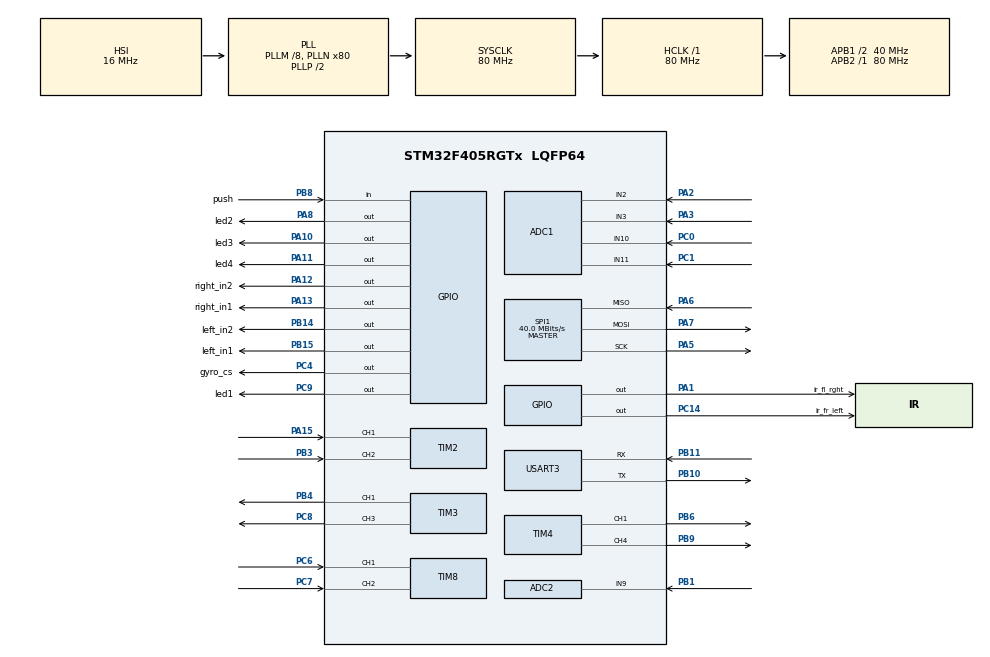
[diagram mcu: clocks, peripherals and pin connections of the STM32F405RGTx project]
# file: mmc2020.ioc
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ADC1.Channel-89\#ChannelRegularConversion=ADC_CHANNEL_10
ADC1.ClockPrescaler=ADC_CLOCK_SYNC_PCLK_DIV4
ADC1.NbrOfConversionFlag=1
ADC1.Rank-89\#ChannelRegularConversion=1
ADC1.SamplingTime-89\#ChannelRegularConversion=ADC_SAMPLETIME_3CYCLES
ADC1.master=1
ADC2.Channel-0\#ChannelRegularConversion=ADC_CHANNEL_9
ADC2.ClockPrescaler=ADC_CLOCK_SYNC_PCLK_DIV4
ADC2.NbrOfConversionFlag=1
ADC2.Rank-0\#ChannelRegularConversion=1
ADC2.SamplingTime-0\#ChannelRegularConversion=ADC_SAMPLETIME_3CYCLES
Mcu.Family=STM32F4
Mcu.Name=STM32F405RGTx
Mcu.Package=LQFP64
NVIC.PriorityGroup=NVIC_PRIORITYGROUP_4
PA1.GPIO_Label=ir_fl_rght
PA1.Signal=GPIO_Output
PA10.GPIO_Label=led3
PA10.Signal=GPIO_Output
PA11.GPIO_Label=led4
PA11.Signal=GPIO_Output
PA12.GPIO_Label=right_in2
PA12.Signal=GPIO_Output
PA13.GPIO_Label=right_in1
PA13.Signal=GPIO_Output
PA15.Signal=S_TIM2_CH1_ETR
PA2.Signal=ADCx_IN2
PA3.Signal=ADCx_IN3
PA5.Mode=Full_Duplex_Master
PA5.Signal=SPI1_SCK
PA6.Mode=Full_Duplex_Master
PA6.Signal=SPI1_MISO
PA7.Mode=Full_Duplex_Master
PA7.Signal=SPI1_MOSI
PA8.GPIO_Label=led2
PA8.Signal=GPIO_Output
PB1.Signal=ADCx_IN9
PB10.Mode=Asynchronous
PB10.Signal=USART3_TX
PB11.Mode=Asynchronous
PB11.Signal=USART3_RX
PB14.GPIO_Label=left_in2
PB14.Signal=GPIO_Output
PB15.GPIO_Label=left_in1
PB15.Signal=GPIO_Output
PB3.Signal=S_TIM2_CH2
PB4.Signal=S_TIM3_CH1
PB6.Signal=S_TIM4_CH1
PB8.GPIO_Label=push
PB8.Signal=GPIO_Input
PB9.Signal=S_TIM4_CH4
PC0.Signal=ADCx_IN10
PC1.Signal=ADCx_IN11
PC14-OSC32_IN.GPIO_Label=ir_fr_left
PC14-OSC32_IN.Signal=GPIO_Output
PC4.GPIO_Label=gyro_cs
PC4.Signal=GPIO_Output
PC6.Signal=S_TIM8_CH1
PC7.Signal=S_TIM8_CH2
PC8.Signal=S_TIM3_CH3
PC9.GPIO_Label=led1
PC9.Signal=GPIO_Output
PH0-OSC_IN.Mode=HSE-External-Oscillator
PH0-OSC_IN.Signal=RCC_OSC_IN
PH1-OSC_OUT.Mode=HSE-External-Oscillator
PH1-OSC_OUT.Signal=RCC_OSC_OUT
ProjectManager.HeapSize=0x200
ProjectManager.StackSize=0x400
ProjectManager.TargetToolchain=Makefile
RCC.48MHZClocksFreq_Value=40000000
RCC.AHBFreq_Value=80000000
RCC.APB1CLKDivider=RCC_HCLK_DIV2
RCC.APB1Freq_Value=40000000
RCC.APB1TimFreq_Value=80000000
RCC.APB2Freq_Value=80000000
RCC.APB2TimFreq_Value=80000000
RCC.CortexFreq_Value=80000000
RCC.HCLKFreq_Value=80000000
RCC.HSE_VALUE=20000000
RCC.HSI_VALUE=16000000
RCC.LSE_VALUE=32768
RCC.PLLM=8
RCC.PLLN=80
RCC.SYSCLKFreq_VALUE=80000000
RCC.SYSCLKSource=RCC_SYSCLKSOURCE_PLLCLK
RCC.VCOOutputFreq_Value=160000000
SH.ADCx_IN10.0=ADC1_IN10,IN10
SH.ADCx_IN11.0=ADC1_IN11,IN11
SH.ADCx_IN2.0=ADC1_IN2,IN2
SH.ADCx_IN3.0=ADC1_IN3,IN3
SH.ADCx_IN9.0=ADC2_IN9,IN9
SH.S_TIM2_CH1_ETR.0=TIM2_CH1,Encoder_Interface
SH.S_TIM2_CH2.0=TIM2_CH2,Encoder_Interface
SH.S_TIM3_CH1.0=TIM3_CH1,PWM Generation1 CH1
SH.S_TIM3_CH3.0=TIM3_CH3,PWM Generation3 CH3
SH.S_TIM4_CH1.0=TIM4_CH1,PWM Generation1 CH1
SH.S_TIM4_CH4.0=TIM4_CH4,PWM Generation4 CH4
SH.S_TIM8_CH1.0=TIM8_CH1,Encoder_Interface
SH.S_TIM8_CH2.0=TIM8_CH2,Encoder_Interface
SPI1.BaudRatePrescaler=SPI_BAUDRATEPRESCALER_2
SPI1.CalculateBaudRate=40.0 MBits/s
SPI1.Direction=SPI_DIRECTION_2LINES
SPI1.Mode=SPI_MODE_MASTER
SPI1.VirtualType=VM_MASTER
TIM3.Channel-PWM\ Generation1\ CH1=TIM_CHANNEL_1
TIM3.Channel-PWM\ Generation3\ CH3=TIM_CHANNEL_3
TIM4.Channel-PWM\ Generation1\ CH1=TIM_CHANNEL_1
TIM4.Channel-PWM\ Generation4\ CH4=TIM_CHANNEL_4
USART3.VirtualMode=VM_ASYNC
board=mmc2020

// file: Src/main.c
/**
  ******************************************************************************
  * @file           : main.c
  * @brief          : Main program body
  ******************************************************************************
  ** This notice applies to any and all portions of this file
  * that are not between comment pairs USER CODE BEGIN and
  * USER CODE END. Other portions of this file, whether
  * inserted by the user or by software development tools
  * are owned by their respective copyright owners.
  *
  * COPYRIGHT(c) 2020 STMicroelectronics
  *
  * Redistribution and use in source and binary forms, with or without modification,
  * are permitted provided that the following conditions are met:
  *   1. Redistributions of source code must retain the above copyright notice,
  *      this list of conditions and the following disclaimer.
  *   2. Redistributions in binary form must reproduce the above copyright notice,
  *      this list of conditions and the following disclaimer in the documentation
  *      and/or other materials provided with the distribution.
  *   3. Neither the name of STMicroelectronics nor the names of its contributors
  *      may be used to endorse or promote products derived from this software
  *      without specific prior written permission.
  *
  * THIS SOFTWARE IS PROVIDED BY THE COPYRIGHT HOLDERS AND CONTRIBUTORS "AS IS"
  * AND ANY EXPRESS OR IMPLIED WARRANTIES, INCLUDING, BUT NOT LIMITED TO, THE
  * IMPLIED WARRANTIES OF MERCHANTABILITY AND FITNESS FOR A PARTICULAR PURPOSE ARE
  * DISCLAIMED. IN NO EVENT SHALL THE COPYRIGHT HOLDER OR CONTRIBUTORS BE LIABLE
  * FOR ANY DIRECT, INDIRECT, INCIDENTAL, SPECIAL, EXEMPLARY, OR CONSEQUENTIAL
  * DAMAGES (INCLUDING, BUT NOT LIMITED TO, PROCUREMENT OF SUBSTITUTE GOODS OR
  * SERVICES; LOSS OF USE, DATA, OR PROFITS; OR BUSINESS INTERRUPTION) HOWEVER
  * CAUSED AND ON ANY THEORY OF LIABILITY, WHETHER IN CONTRACT, STRICT LIABILITY,
  * OR TORT (INCLUDING NEGLIGENCE OR OTHERWISE) ARISING IN ANY WAY OUT OF THE USE
  * OF THIS SOFTWARE, EVEN IF ADVISED OF THE POSSIBILITY OF SUCH DAMAGE.
  *
  ******************************************************************************
  */
#include "main.h"
#include "stm32f4xx_hal.h"
#include "adc.h"
#include "spi.h"
#include "tim.h"
#include "usart.h"
#include "gpio.h"

/* USER CODE BEGIN Includes */
#include "stdint.h"
/* USER CODE END Includes */

/* USER CODE BEGIN PV */
#define TRUE 1
#define FALSE 0
/* Private variables ---------------------------------------------------------*/

/* USER CODE END PV */

void SystemClock_Config(void);

/* USER CODE BEGIN PFP */
/* Private function prototypes -----------------------------------------------*/

/* USER CODE END PFP */

int main(void)
{

  /* MCU Configuration----------------------------------------------------------*/

  /* Reset of all peripherals, Initializes the Flash interface and the Systick. */
  HAL_Init();

  /* Configure the system clock */
  SystemClock_Config();

  /* Initialize all configured peripherals */
  MX_GPIO_Init();
  MX_ADC1_Init();
  MX_SPI1_Init();
  MX_TIM8_Init();
  MX_TIM2_Init();
  MX_TIM3_Init();
  MX_TIM4_Init();
  MX_USART3_UART_Init();
  MX_ADC2_Init();
  /* USER CODE BEGIN 2 */
  buzzerPwmOut(99,C_SCALE);
  HAL_Delay(1000);
  buzzerPwmOut(0,NORMAL);
  /* USER CODE END 2 */

  /* Infinite loop */
  /* USER CODE BEGIN WHILE */
  while (1)
  {
    if(Push()==TRUE){
      for(uint8_t i=0;i<16;i++){
        Led(i);
        HAL_Delay(500);
      }
    }
  /* USER CODE END WHILE */

  }

}

void SystemClock_Config(void)
{

  RCC_OscInitTypeDef RCC_OscInitStruct;
  RCC_ClkInitTypeDef RCC_ClkInitStruct;

    /**Configure the main internal regulator output voltage
    */
  __HAL_RCC_PWR_CLK_ENABLE();

  __HAL_PWR_VOLTAGESCALING_CONFIG(PWR_REGULATOR_VOLTAGE_SCALE1);

    /**Initializes the CPU, AHB and APB busses clocks
    */
  RCC_OscInitStruct.OscillatorType = RCC_OSCILLATORTYPE_HSI;
  RCC_OscInitStruct.HSIState = RCC_HSI_ON;
  RCC_OscInitStruct.HSICalibrationValue = 16;
  RCC_OscInitStruct.PLL.PLLState = RCC_PLL_ON;
  RCC_OscInitStruct.PLL.PLLSource = RCC_PLLSOURCE_HSI;
  RCC_OscInitStruct.PLL.PLLM = 8;
  RCC_OscInitStruct.PLL.PLLN = 80;
  RCC_OscInitStruct.PLL.PLLP = RCC_PLLP_DIV2;
  RCC_OscInitStruct.PLL.PLLQ = 4;
  if (HAL_RCC_OscConfig(&RCC_OscInitStruct) != HAL_OK)
  {
    _Error_Handler(__FILE__, __LINE__);
  }

    /**Initializes the CPU, AHB and APB busses clocks
    */
  RCC_ClkInitStruct.ClockType = RCC_CLOCKTYPE_HCLK|RCC_CLOCKTYPE_SYSCLK
                              |RCC_CLOCKTYPE_PCLK1|RCC_CLOCKTYPE_PCLK2;
  RCC_ClkInitStruct.SYSCLKSource = RCC_SYSCLKSOURCE_PLLCLK;
  RCC_ClkInitStruct.AHBCLKDivider = RCC_SYSCLK_DIV1;
  RCC_ClkInitStruct.APB1CLKDivider = RCC_HCLK_DIV2;
  RCC_ClkInitStruct.APB2CLKDivider = RCC_HCLK_DIV1;

  if (HAL_RCC_ClockConfig(&RCC_ClkInitStruct, FLASH_LATENCY_2) != HAL_OK)
  {
    _Error_Handler(__FILE__, __LINE__);
  }

    /**Configure the Systick interrupt time
    */
  HAL_SYSTICK_Config(HAL_RCC_GetHCLKFreq()/1000);

    /**Configure the Systick
    */
  HAL_SYSTICK_CLKSourceConfig(SYSTICK_CLKSOURCE_HCLK);

  /* SysTick_IRQn interrupt configuration */
  HAL_NVIC_SetPriority(SysTick_IRQn, 0, 0);
}

void _Error_Handler(char *file, int line)
{
  while(1)
  {
  }
}

/************************ (C) COPYRIGHT STMicroelectronics *****END OF FILE****/
